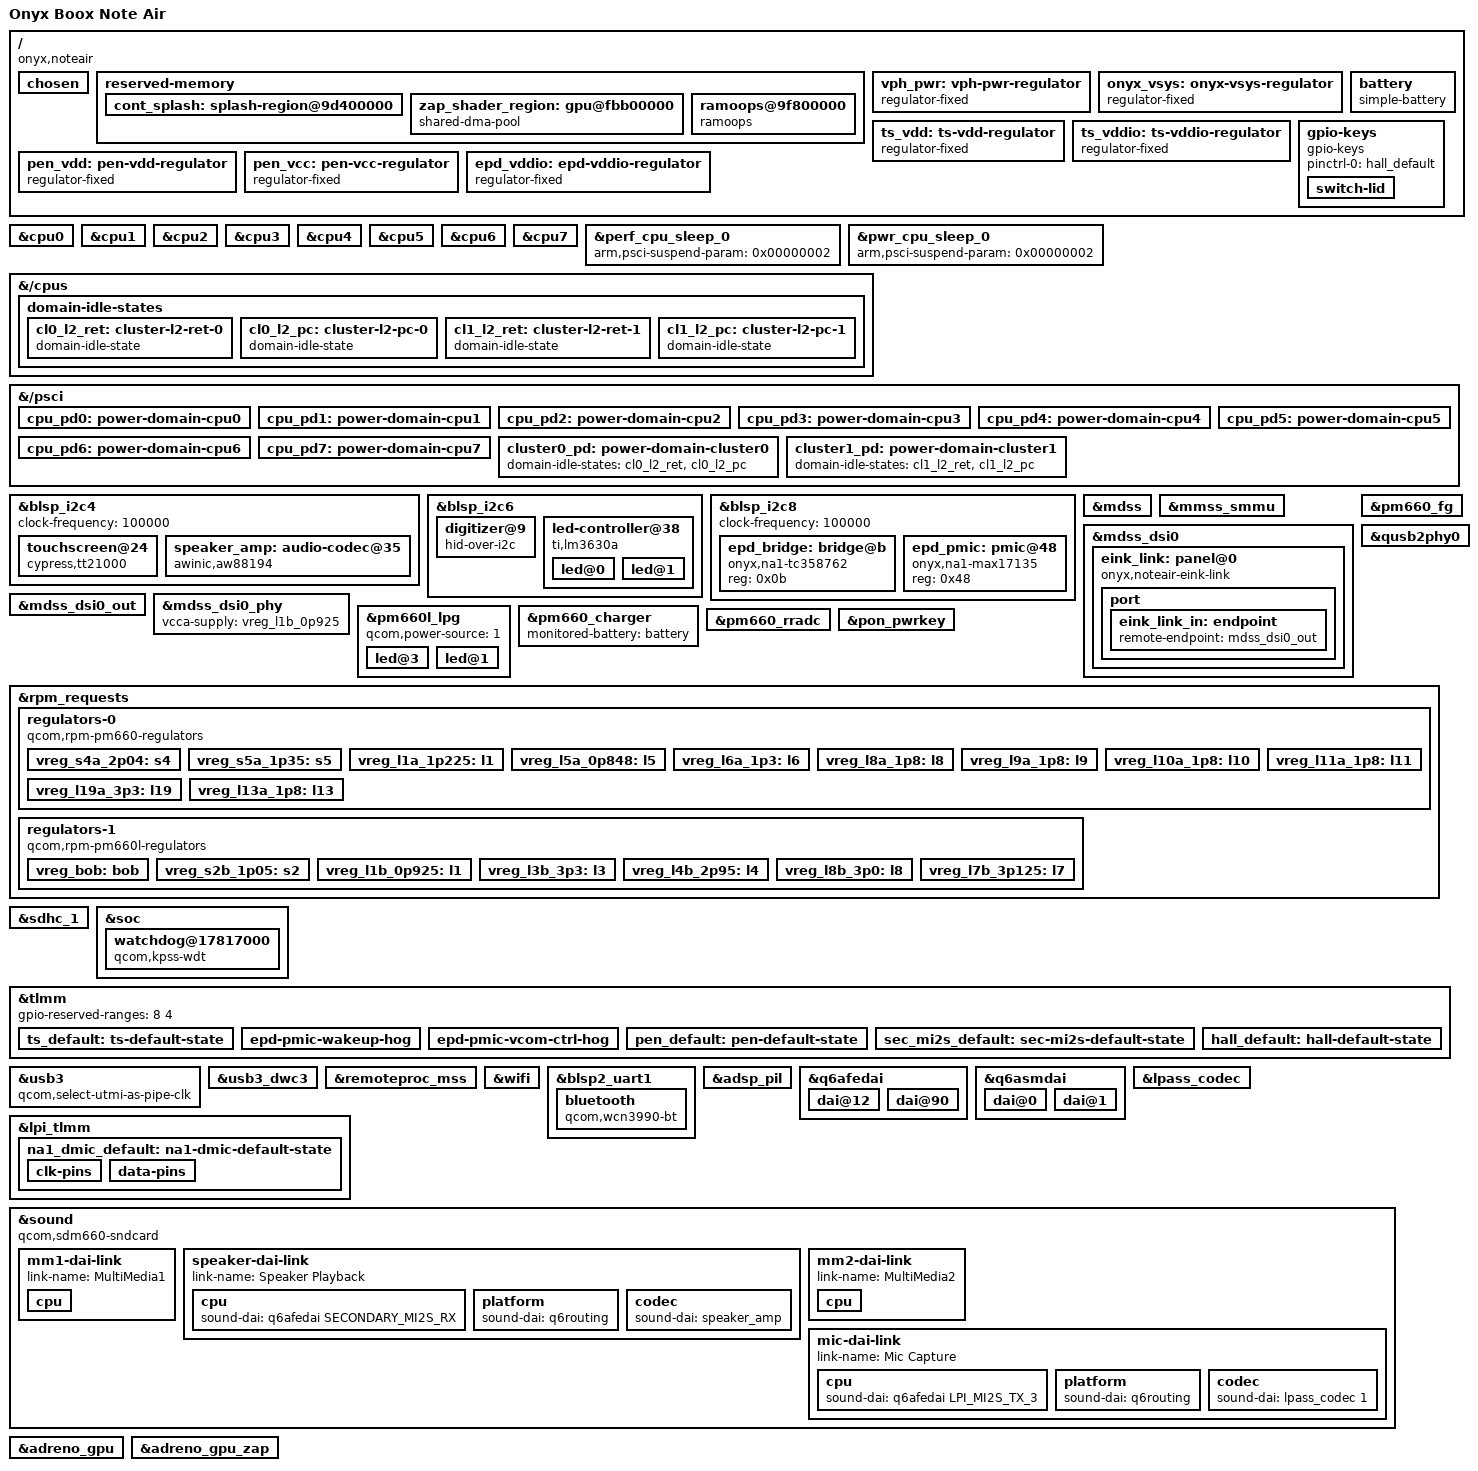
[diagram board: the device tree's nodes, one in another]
// SPDX-License-Identifier: GPL-2.0-only
/*
 * Onyx Boox Note Air (NA1) — bring-up device tree for the sdm660-mainline kernel.
 *
 * Source of every board fact: the stock Onyx DT (model
 * "SDM 636 PM660 + PM660L MTP NoteAir V02"). Template: sdm636-asus-x00td.dts.
 *
 * First bring-up: boot, pstore, USB peripheral, eMMC, watchdog, LEDs,
 * frontlight, touch, hall, charger + fuel gauge. The e-ink link, radios,
 * audio, GPU and pen came later (sections below).
 *
 * e-ink path (MDSS DPU -> DSI0 cmd mode -> TC358762 bridge -> panel, MAX17135
 * PMIC): panel-onyx-na1-link owns the link, the bridge (I2C + gpios) and the
 * PMIC rails (ENABLE reg only, gated by its hv parameter). The MAX17135 holds
 * VCOM in its NVM — never probe it with a generic driver and never write its
 * VCOM registers.
 * Also left out: Wacom pen (no mainline driver for onyx,wacom_i2c), WiFi/BT,
 * modem, audio, GPU.
 */

/dts-v1/;

#include "sdm636.dtsi"
#include "pm660.dtsi"
#include "pm660l.dtsi"
#include <dt-bindings/input/input.h>
#include <dt-bindings/input/gpio-keys.h>
#include <dt-bindings/leds/common.h>
#include <dt-bindings/sound/qcom,q6asm.h>

/*
 * Stock ramoops lives at 0x9f800000 (512 KiB). sdm630.dtsi puts a no-map
 * venus region at the same address; we don't use video decode, so the venus
 * region and device go, and ramoops takes the stock place and layout.
 */
/delete-node/ &venus_region;
/delete-node/ &venus;
/*
 * GPU zap shader: stock loads it at 0xfbb00000..0xfbb02000 (dmesg s70:
 * "subsys-pil-tz soc:qcom,kgsl-hyp: a512_zap: loading from 0xfbb00000");
 * sdm630.dtsi's region sits at 0xfed00000. As lavender does for its board.
 */
/delete-node/ &zap_shader_region;

/ {
	model = "Onyx Boox Note Air";
	compatible = "onyx,noteair", "qcom,sdm636";
	chassis-type = "tablet";

	/* ABL picks the appended DTB by these; values copied from the stock DT. */
	qcom,msm-id = <0x159 0x0>;
	qcom,board-id = <0x8 0x0>;
	qcom,pmic-id = <0x1001b 0x101011a 0x0 0x0 0x1001b 0x201011a 0x0 0x0 0x1001b 0x102001a 0x0 0x0>;

	/* No serial console: no known UART pads, and it hung suspend. */
	chosen {
	};

	reserved-memory {
		/* ABL leaves the display pipeline scanning out of this; keep it untouched. */
		cont_splash: splash-region@9d400000 {
			reg = <0x0 0x9d400000 0x0 0x23ff000>;
			no-map;
		};

		/*
		 * Same place and zone sizes as the stock kernel (ecc 0 on both), so
		 * each kernel can read what the other left: the stock pmOS initramfs
		 * saves it to /var/log/pstore/ on the next boot. Zones: dmesg 1x128K,
		 * console 128K, ftrace 64K, pmsg 64K. Survives warm reset only.
		 */
		zap_shader_region: gpu@fbb00000 {
			compatible = "shared-dma-pool";
			reg = <0x0 0xfbb00000 0x0 0x2000>;
			no-map;
		};

		ramoops@9f800000 {
			compatible = "ramoops";
			reg = <0x0 0x9f800000 0x0 0x80000>;
			record-size = <0x20000>;
			console-size = <0x20000>;
			ftrace-size = <0x10000>;
			pmsg-size = <0x10000>;
		};
	};

	vph_pwr: vph-pwr-regulator {
		compatible = "regulator-fixed";
		regulator-name = "vph_pwr";
		regulator-min-microvolt = <3700000>;
		regulator-max-microvolt = <3700000>;
		regulator-always-on;
		regulator-boot-on;
	};

	/* Stock "onyx-vsys": 1.8 V switch on TLMM 40, feeds the LM3630A. */
	onyx_vsys: onyx-vsys-regulator {
		compatible = "regulator-fixed";
		regulator-name = "onyx-vsys";
		regulator-min-microvolt = <1800000>;
		regulator-max-microvolt = <1800000>;
		gpio = <&tlmm 40 GPIO_ACTIVE_HIGH>;
		enable-active-high;
		regulator-always-on;
		regulator-boot-on;
	};

	/* Touch power switches (stock onyx-tp,vcc-ctrl-gpio / vdd-ctrl-gpio). */
	ts_vdd: ts-vdd-regulator {
		compatible = "regulator-fixed";
		regulator-name = "ts_vdd";
		regulator-min-microvolt = <3300000>;
		regulator-max-microvolt = <3300000>;
		gpio = <&tlmm 61 GPIO_ACTIVE_HIGH>;
		enable-active-high;
		vin-supply = <&vreg_l3b_3p3>;
		startup-delay-us = <5000>;
	};

	ts_vddio: ts-vddio-regulator {
		compatible = "regulator-fixed";
		regulator-name = "ts_vddio";
		regulator-min-microvolt = <1800000>;
		regulator-max-microvolt = <1800000>;
		gpio = <&tlmm 62 GPIO_ACTIVE_HIGH>;
		enable-active-high;
		vin-supply = <&vreg_l11a_1p8>;
		startup-delay-us = <5000>;
	};

	/*
	 * Pen (Wacom EMR, HID-over-I2C 2D1F:012B at blsp_i2c6 0x09; stock
	 * onyx,wacom_i2c) power switches: stock onyx-tp,vdd-ctrl-gpio 64 (1.8 V
	 * from pm660 l11) and vcc-ctrl-gpio 63 (3.0 V from pm660l l3).
	 * Bring-up: the rails are always on, so the digitizer answers
	 * before i2c-hid-of (a module) is loaded: reset (gpio75, unowned until
	 * then) is driven by hand with gpioset, the IRQ idle level read with
	 * gpioget and the HID descriptor with i2ctransfer.
	 * Drop always-on once the
	 * digitizer node below is confirmed.
	 */
	pen_vdd: pen-vdd-regulator {
		compatible = "regulator-fixed";
		regulator-name = "pen_vdd";
		regulator-min-microvolt = <1800000>;
		regulator-max-microvolt = <1800000>;
		gpio = <&tlmm 64 GPIO_ACTIVE_HIGH>;
		enable-active-high;
		vin-supply = <&vreg_l11a_1p8>;
		startup-delay-us = <5000>;
		regulator-always-on;
	};

	pen_vcc: pen-vcc-regulator {
		compatible = "regulator-fixed";
		regulator-name = "pen_vcc";
		regulator-min-microvolt = <3000000>;
		regulator-max-microvolt = <3000000>;
		gpio = <&tlmm 63 GPIO_ACTIVE_HIGH>;
		enable-active-high;
		vin-supply = <&vreg_l3b_3p3>;
		startup-delay-us = <5000>;
		regulator-always-on;
	};

	/* Stock "vddio_gpio_regulator": 3.3 V switch on TLMM 35 (e-ink bridge + PMIC IO). */
	epd_vddio: epd-vddio-regulator {
		compatible = "regulator-fixed";
		regulator-name = "epd_vddio";
		regulator-min-microvolt = <3300000>;
		regulator-max-microvolt = <3300000>;
		gpio = <&tlmm 35 GPIO_ACTIVE_HIGH>;
		enable-active-high;
		vin-supply = <&onyx_vsys>;
	};

	/*
	 * Stock battery profile "4616397_idea_h6620_byd_3000mah": 3000 mAh, float 4.40 V,
	 * FG cutoff 3.30 V; stock charger fcc-max 1.5 A. The charger driver programs the
	 * float voltage and charge current from these — keep them at the stock values.
	 */
	battery: battery {
		compatible = "simple-battery";
		charge-full-design-microamp-hours = <3000000>;
		voltage-min-design-microvolt = <3300000>;
		voltage-max-design-microvolt = <4400000>;
		constant-charge-current-max-microamp = <1500000>;
	};

	gpio-keys {
		compatible = "gpio-keys";
		pinctrl-names = "default";
		pinctrl-0 = <&hall_default>;

		/* Stock onyx-hall: TLMM 105, pulled up, low = cover closed. ABL reads it too. */
		switch-lid {
			label = "Hall Effect Sensor";
			gpios = <&tlmm 105 GPIO_ACTIVE_LOW>;
			linux,input-type = <EV_SW>;
			linux,code = <SW_LID>;
			linux,can-disable;
			wakeup-source;
		};

		/* The stock DT also has volume-up on PM660L gpio 7, but the NA1 has no such button. */
	};
};

/* Stock i2c@c178000: Cypress/Parade touch. */
/*
 * No cpufreq on mainline yet: the clusters stay where the boot chain left them, which is
 * silver (0x801, &cpu4-7) at 1382.4 MHz and gold (0x800, &cpu0-3) at only 600 MHz (measured,
 * cycles/s). sdm660.dtsi's 1024/640 then sends heavy work to the SLOWER cores. Measured with
 * both pinned: zlib 3.6 s silver vs 5.9 s gold, Python 2.2 vs 2.5 s -> gold ~0.6-0.9x silver.
 * sdm636-cpufreq.dtsi (included below) undoes these now that cpufreq works;
 * they stay for a build without it.
 */
&cpu0 {
	capacity-dmips-mhz = <768>;
	/delete-property/ cpu-idle-states;
	power-domains = <&cpu_pd0>;
	power-domain-names = "psci";
};
&cpu1 {
	capacity-dmips-mhz = <768>;
	/delete-property/ cpu-idle-states;
	power-domains = <&cpu_pd1>;
	power-domain-names = "psci";
};
&cpu2 {
	capacity-dmips-mhz = <768>;
	/delete-property/ cpu-idle-states;
	power-domains = <&cpu_pd2>;
	power-domain-names = "psci";
};
&cpu3 {
	capacity-dmips-mhz = <768>;
	/delete-property/ cpu-idle-states;
	power-domains = <&cpu_pd3>;
	power-domain-names = "psci";
};
&cpu4 {
	capacity-dmips-mhz = <1024>;
	/delete-property/ cpu-idle-states;
	power-domains = <&cpu_pd4>;
	power-domain-names = "psci";
};
&cpu5 {
	capacity-dmips-mhz = <1024>;
	/delete-property/ cpu-idle-states;
	power-domains = <&cpu_pd5>;
	power-domain-names = "psci";
};
&cpu6 {
	capacity-dmips-mhz = <1024>;
	/delete-property/ cpu-idle-states;
	power-domains = <&cpu_pd6>;
	power-domain-names = "psci";
};
&cpu7 {
	capacity-dmips-mhz = <1024>;
	/delete-property/ cpu-idle-states;
	power-domains = <&cpu_pd7>;
	power-domain-names = "psci";
};

/*
 * CPU / cluster idle. The NA1's TZ runs PSCI in OS-initiated mode and
 * refuses platform-coordinated ("psci: [Firmware Bug]: failed to set PC mode:
 * -3" = DENIED), so sdm630.dtsi's flat cluster states (0x400000f2..f4) were
 * all rejected (millions of times; the clusters never powered down), and its
 * core retention 0x40000002 as well (retention is no power-down: bit 30 = 0).
 * State IDs as the stock 4.4 lpm-levels composes them: cpu mode [3:0] (2 ret,
 * 3 pc), L2 mode [7:4] (3 ret, 4 pc), affinity level [25:24], bit 30 = cpu
 * power-down. A cluster state is the whole composite, requested by the last
 * CPU of the cluster going down (OSI, genpd). The system/CCI level (needs an
 * RPM handshake) is left out.
 */
&perf_cpu_sleep_0 { arm,psci-suspend-param = <0x00000002>; };
&pwr_cpu_sleep_0 { arm,psci-suspend-param = <0x00000002>; };

&{/cpus} {
	domain-idle-states {
		cl0_l2_ret: cluster-l2-ret-0 {
			compatible = "domain-idle-state";
			arm,psci-suspend-param = <0x41000033>;
			entry-latency-us = <338>;
			exit-latency-us = <423>;
			min-residency-us = <2000>;
		};
		cl0_l2_pc: cluster-l2-pc-0 {
			compatible = "domain-idle-state";
			arm,psci-suspend-param = <0x41000043>;
			entry-latency-us = <515>;
			exit-latency-us = <1821>;
			min-residency-us = <5000>;
		};
		cl1_l2_ret: cluster-l2-ret-1 {
			compatible = "domain-idle-state";
			arm,psci-suspend-param = <0x41000033>;
			entry-latency-us = <332>;
			exit-latency-us = <368>;
			min-residency-us = <2000>;
		};
		cl1_l2_pc: cluster-l2-pc-1 {
			compatible = "domain-idle-state";
			arm,psci-suspend-param = <0x41000043>;
			entry-latency-us = <545>;
			exit-latency-us = <1609>;
			min-residency-us = <5000>;
		};
	};
};

&{/psci} {
	cpu_pd0: power-domain-cpu0 {
		#power-domain-cells = <0>;
		power-domains = <&cluster1_pd>;
		domain-idle-states = <&perf_cpu_sleep_0 &perf_cpu_sleep_1>;
	};
	cpu_pd1: power-domain-cpu1 {
		#power-domain-cells = <0>;
		power-domains = <&cluster1_pd>;
		domain-idle-states = <&perf_cpu_sleep_0 &perf_cpu_sleep_1>;
	};
	cpu_pd2: power-domain-cpu2 {
		#power-domain-cells = <0>;
		power-domains = <&cluster1_pd>;
		domain-idle-states = <&perf_cpu_sleep_0 &perf_cpu_sleep_1>;
	};
	cpu_pd3: power-domain-cpu3 {
		#power-domain-cells = <0>;
		power-domains = <&cluster1_pd>;
		domain-idle-states = <&perf_cpu_sleep_0 &perf_cpu_sleep_1>;
	};
	cpu_pd4: power-domain-cpu4 {
		#power-domain-cells = <0>;
		power-domains = <&cluster0_pd>;
		domain-idle-states = <&pwr_cpu_sleep_0 &pwr_cpu_sleep_1>;
	};
	cpu_pd5: power-domain-cpu5 {
		#power-domain-cells = <0>;
		power-domains = <&cluster0_pd>;
		domain-idle-states = <&pwr_cpu_sleep_0 &pwr_cpu_sleep_1>;
	};
	cpu_pd6: power-domain-cpu6 {
		#power-domain-cells = <0>;
		power-domains = <&cluster0_pd>;
		domain-idle-states = <&pwr_cpu_sleep_0 &pwr_cpu_sleep_1>;
	};
	cpu_pd7: power-domain-cpu7 {
		#power-domain-cells = <0>;
		power-domains = <&cluster0_pd>;
		domain-idle-states = <&pwr_cpu_sleep_0 &pwr_cpu_sleep_1>;
	};
	/* cpu4-7 (the "pwr" states in sdm630.dtsi) */
	cluster0_pd: power-domain-cluster0 {
		#power-domain-cells = <0>;
		domain-idle-states = <&cl0_l2_ret &cl0_l2_pc>;
	};
	/* cpu0-3 */
	cluster1_pd: power-domain-cluster1 {
		#power-domain-cells = <0>;
		domain-idle-states = <&cl1_l2_ret &cl1_l2_pc>;
	};
};

&blsp_i2c4 {
	clock-frequency = <100000>;
	status = "okay";

	touchscreen@24 {
		compatible = "cypress,tt21000";
		reg = <0x24>;
		/* level, not edge: INT stays low while reports are
		 * queued, so a missed falling edge left touch dead for good
		 * (irq count frozen, na1-touchd gone) */
		interrupts-extended = <&tlmm 67 IRQ_TYPE_LEVEL_LOW>;
		reset-gpios = <&tlmm 66 GPIO_ACTIVE_LOW>;
		vdd-supply = <&ts_vdd>;
		vddio-supply = <&ts_vddio>;
		pinctrl-names = "default";
		pinctrl-0 = <&ts_default>;
		/* report like the stock cyttsp5_mt (na1-touchd and the X
		 * calibration matrix assume its axes): mainline's y runs the
		 * other way (portrait taps came out mirrored left/right) */
		touchscreen-inverted-y;
	};

	/*
	 * Speaker amp: Awinic AW88194 (chip id 0x1806), fed from SEC_MI2S SD1.
	 * Stock: aw881xx_smartpa@35, reset-gpio TLMM 94, no irq, no supply;
	 * its tuning files come from the vendor partition (na1-ml-radio links
	 * them to /lib/firmware/awinic).
	 */
	speaker_amp: audio-codec@35 {
		compatible = "awinic,aw88194";
		reg = <0x35>;
		reset-gpios = <&tlmm 94 GPIO_ACTIVE_LOW>;
		firmware-name = "awinic/aw881xx_na1_spk";
		#sound-dai-cells = <0>;
	};
};

/* Stock i2c@c1b6000: LM3630A frontlight, Wacom pen @09 (left out), NFC (disabled on stock). */
&blsp_i2c6 {
	status = "okay";

	/*
	 * Pen: stock wacom@09 (onyx,wacom_i2c) = HID-over-I2C Wacom EMR 2D1F:012B.
	 * UNCONFIRMED until probed by hand: IRQ polarity (level-low per the
	 * HID-over-I2C spec and the stock pull-up; stock requests flag 1 =
	 * rising edge) and reset polarity (assumed RESET_N).
	 */
	digitizer@9 {
		compatible = "hid-over-i2c";
		reg = <0x09>;
		hid-descr-addr = <0x0001>;
		interrupts-extended = <&tlmm 74 IRQ_TYPE_LEVEL_LOW>;
		reset-gpios = <&tlmm 75 GPIO_ACTIVE_LOW>;
		vdd-supply = <&pen_vdd>;
		vddl-supply = <&pen_vcc>;
		post-power-on-delay-ms = <20>;
		post-reset-deassert-delay-ms = <100>;
		pinctrl-names = "default";
		pinctrl-0 = <&pen_default>;
	};

	led-controller@38 {
		compatible = "ti,lm3630a";
		reg = <0x38>;
		enable-gpios = <&tlmm 76 GPIO_ACTIVE_HIGH>;
		#address-cells = <1>;
		#size-cells = <0>;

		/*
		 * Two strings (warm/cold). A low default on bank A doubles as a
		 * "kernel got this far" signal: the e-ink shows nothing new.
		 */
		led@0 {
			reg = <0>;
			led-sources = <0>;
			label = "frontlight-a";
			default-brightness = <24>;
			max-brightness = <255>;
		};

		led@1 {
			reg = <1>;
			led-sources = <1>;
			label = "frontlight-b";
			default-brightness = <0>;
			max-brightness = <255>;
		};
	};
};

/*
 * Stock i2c@c1b8000 (100 kHz): TC358762 @0b and MAX17135 @48 (e-ink). Both
 * nodes are plain I2C clients with Onyx-specific compatibles that no driver
 * binds: panel-onyx-na1-link reaches them by phandle and sequences them. The
 * MAX17135 VCOM lives in its NVM: never write it (regs 0x08/0x0C), and never
 * bind a generic max17135/regulator driver here.
 */
&blsp_i2c8 {
	status = "okay";
	clock-frequency = <100000>;

	epd_bridge: bridge@b {
		compatible = "onyx,na1-tc358762";
		reg = <0x0b>;
	};

	epd_pmic: pmic@48 {
		compatible = "onyx,na1-max17135";
		reg = <0x48>;
	};
};

/*
 * EPDC bring-up step 2: the DSI link alone. Stock DSI0: vdda 1.2 V (pm660
 * l1), PHY 0.9 V (pm660l l1), 2 lanes, command mode. Stock's LCD-template
 * extras (lab/ibb bias, reset gpio 53, TE gpio 59) are not used by the e-ink
 * path and are left out. No TE: DPU's watchdog timer paces command mode.
 */
&mdss {
	status = "okay";
};

&mmss_smmu {
	status = "okay";
};

&mdss_dsi0 {
	#address-cells = <1>;
	#size-cells = <0>;

	vdd-supply = <&vreg_l1b_0p925>;
	/*
	 * Stock vdda-1p2-supply = pm660_l6 (1.2-1.32 V, 12.56 mA), the LDO it
	 * shares with the WCN RF and the BT PA; l1a was the reference board's.
	 * With l1a here the DSI analog side ran only while WiFi or BT held l6,
	 * and the PLL died when the last of them let go mid-link (the power-key
	 * display stall, 2026-10-02).
	 */
	vdda-supply = <&vreg_l6a_1p3>;
	/*
	 * Stock command-mode byte order (downstream "rgb_swap_grb"; stock
	 * onyx_epdc_sdm660_mdp_reg_update writes CMD_CFG0 = 0x40008). With an
	 * XBGR8888 framebuffer (SSPP unpack 0x03010002 = stock) the wire carries
	 * the stock frame words byte-for-byte. Patch 0003.
	 */
	qcom,cmd-rgb-swap-grb;
	status = "okay";

	/*
	 * Stock tc358762@0b: osc_enable 55, mode0 43 (= MD0), reset 42 (active
	 * low), vddc 1.2 V switch 45, vdd1v8 pm660_l11, vddio TLMM 35 switch.
	 * Stock max17135@48: vdd (V3P3) pm660l_l8 3.0 V, pwrgood 52.
	 */
	eink_link: panel@0 {
		compatible = "onyx,noteair-eink-link";
		reg = <0>;
		/* the host's link clocks: HV only while they run at the mode's rate */
		clocks = <&mmcc MDSS_PCLK0_CLK>, <&mmcc MDSS_BYTE0_CLK>,
			 <&rpmcc RPM_SMD_RF_CLK1_PIN>;
		clock-names = "pclk", "byte", "rfclk";
		/* VDDMX held while the link is up (driver param mx_level, default
		 * off): the power-key display stall, 2026-10-02 */
		power-domains = <&rpmpd RPMPD_VDDMX_AO>;
		power-domain-names = "mx";
		/* the DSI LDOs' parents: load votes while the link is up
		 * (driver params hold_rfclk / rail_load_ua, default off) */
		s5a-supply = <&vreg_s5a_1p35>;
		s2b-supply = <&vreg_s2b_1p05>;
		/* the WCN rails, held while the link is up (param hold_wcn, default off) */
		wcn-l5-supply = <&vreg_l5a_0p848>;
		wcn-l9-supply = <&vreg_l9a_1p8>;
		wcn-l6-supply = <&vreg_l6a_1p3>;
		wcn-l19-supply = <&vreg_l19a_3p3>;

		onyx,bridge = <&epd_bridge>;
		onyx,pmic = <&epd_pmic>;
		osc-gpios = <&tlmm 55 GPIO_ACTIVE_HIGH>;
		mode0-gpios = <&tlmm 43 GPIO_ACTIVE_HIGH>;
		reset-gpios = <&tlmm 42 GPIO_ACTIVE_LOW>;
		vddc-gpios = <&tlmm 45 GPIO_ACTIVE_HIGH>;
		pmic-pwrgood-gpios = <&tlmm 52 GPIO_ACTIVE_HIGH>;
		vdd1v8-supply = <&vreg_l11a_1p8>;
		vddio-supply = <&epd_vddio>;
		v3p3-supply = <&vreg_l8b_3p0>;

		port {
			eink_link_in: endpoint {
				remote-endpoint = <&mdss_dsi0_out>;
			};
		};
	};
};

&mdss_dsi0_out {
	data-lanes = <0 1>;
	qcom,te-source = "timer0";
	remote-endpoint = <&eink_link_in>;
};

&mdss_dsi0_phy {
	vcca-supply = <&vreg_l1b_0p925>;
	status = "okay";
};

&pm660l_lpg {
	#address-cells = <1>;
	#size-cells = <0>;
	qcom,power-source = <1>;
	status = "okay";

	/* Tri-LED behind the power-button pinhole; channel 3 = red (as lavender). */
	led@3 {
		reg = <3>;
		color = <LED_COLOR_ID_RED>;
		function = LED_FUNCTION_HEARTBEAT;
		/*
		 * No default trigger: the heartbeat was for the
		 * overnight-stall hunt and cost ~10 wakeups/s + the LED current.
		 * Debug: echo heartbeat > /sys/class/leds/red:heartbeat/trigger
		 */
	};

	/* Assumed blue (stock qcom,id 5); lights solid on panic. */
	led@1 {
		reg = <1>;
		color = <LED_COLOR_ID_BLUE>;
		function = LED_FUNCTION_INDICATOR;
		linux,default-trigger = "panic";
	};
};

&pm660_charger {
	monitored-battery = <&battery>;
	status = "okay";
};

&pm660_fg {
	monitored-battery = <&battery>;
	power-supplies = <&pm660_charger>;
	status = "okay";
};

&pm660_rradc {
	status = "okay";
};

&pon_pwrkey {
	status = "okay";
};

&qusb2phy0 {
	vdd-supply = <&vreg_l1b_0p925>;
	vdda-pll-supply = <&vreg_l10a_1p8>;
	vdda-phy-dpdm-supply = <&vreg_l7b_3p125>;
	status = "okay";
};

&rpm_requests {
	regulators-0 {
		compatible = "qcom,rpm-pm660-regulators";

		vdd_s1-supply = <&vph_pwr>;
		vdd_s2-supply = <&vph_pwr>;
		vdd_s3-supply = <&vph_pwr>;
		vdd_s4-supply = <&vph_pwr>;
		vdd_s5-supply = <&vph_pwr>;
		vdd_s6-supply = <&vph_pwr>;

		vdd_l1_l6_l7-supply = <&vreg_s5a_1p35>;
		vdd_l2_l3-supply = <&vreg_s2b_1p05>;
		vdd_l5-supply = <&vreg_s2b_1p05>;
		vdd_l8_l9_l10_l11_l12_l13_l14-supply = <&vreg_s4a_2p04>;
		vdd_l15_l16_l17_l18_l19-supply = <&vreg_bob>;

		/* S1A-S3A are CPR/OSM-managed; not touched. */

		vreg_s4a_2p04: s4 {
			regulator-min-microvolt = <1805000>;
			regulator-max-microvolt = <2040000>;
			regulator-enable-ramp-delay = <200>;
			regulator-always-on;
		};

		/*
		 * Our vote 1.328 V, not 1.224 (2026-10-02, the power-key display
		 * stall): s5a feeds l1a (DSI vdda, 1.256 V out) and l6a (WCN RF).
		 * With WiFi on, l6a's need held s5a at 1.328 V; WCN off dropped it
		 * to 1.296 V (SPMI readback), and a WCN shutdown within ~5 ms of
		 * the DSI PLL lock killed the PLL every time (wififlap fine sweep,
		 * 3/3 real presses). Votes only while a child is on.
		 */
		vreg_s5a_1p35: s5 {
			regulator-min-microvolt = <1328000>;
			regulator-max-microvolt = <1350000>;
			regulator-enable-ramp-delay = <200>;
			regulator-allow-set-load;
		};

		/* stock pm660_l1: only the UFS ref clock (not on this eMMC board);
		 * unused here since the DSI vdda moved to l6 (2026-10-02) */
		vreg_l1a_1p225: l1 {
			regulator-min-microvolt = <1200000>;
			regulator-max-microvolt = <1250000>;
			regulator-enable-ramp-delay = <250>;
			regulator-allow-set-load;
		};

		/* WCN3990 cx/mx (stock pm660_l5 0.848 V) */
		vreg_l5a_0p848: l5 {
			regulator-min-microvolt = <525000>;
			regulator-max-microvolt = <950000>;
			regulator-enable-ramp-delay = <250>;
		};

		/* DSI0 vdda (stock "vdda-1p2" 1.2-1.32 V) + WCN3990 rfa + BT pa
		 * (stock pm660_l6 1.2-1.37 V) */
		vreg_l6a_1p3: l6 {
			regulator-min-microvolt = <1200000>;
			regulator-max-microvolt = <1370000>;
			regulator-enable-ramp-delay = <250>;
			regulator-allow-set-load;
		};

		/* eMMC vqmmc (stock pm660_l8 1.75–1.9 V) */
		vreg_l8a_1p8: l8 {
			regulator-min-microvolt = <1750000>;
			regulator-max-microvolt = <1800000>;
			regulator-enable-ramp-delay = <250>;
			regulator-system-load = <325000>;
			regulator-allow-set-load;
		};

		/* WCN3990 xo / BT core (stock pm660_l9 1.75–1.9 V) */
		vreg_l9a_1p8: l9 {
			regulator-min-microvolt = <1750000>;
			regulator-max-microvolt = <1900000>;
			regulator-enable-ramp-delay = <250>;
			regulator-allow-set-load;
		};

		vreg_l10a_1p8: l10 {
			regulator-min-microvolt = <1780000>;
			regulator-max-microvolt = <1950000>;
			regulator-enable-ramp-delay = <250>;
			regulator-allow-set-load;
		};

		/* touch vddio source (stock pm660_l11 1.78–1.95 V) */
		vreg_l11a_1p8: l11 {
			regulator-min-microvolt = <1780000>;
			regulator-max-microvolt = <1950000>;
			regulator-enable-ramp-delay = <250>;
		};

		/* WCN3990 ch0 / BT ldo (stock pm660_l19 3.312–3.4 V) */
		vreg_l19a_3p3: l19 {
			regulator-min-microvolt = <3312000>;
			regulator-max-microvolt = <3400000>;
			regulator-enable-ramp-delay = <250>;
			regulator-allow-set-load;
		};

		/* LPDDR4 supply: never turn off. */
		vreg_l13a_1p8: l13 {
			regulator-min-microvolt = <1780000>;
			regulator-max-microvolt = <1950000>;
			regulator-enable-ramp-delay = <250>;
			regulator-boot-on;
			regulator-always-on;
		};
	};

	regulators-1 {
		compatible = "qcom,rpm-pm660l-regulators";

		vdd_s1-supply = <&vph_pwr>;
		vdd_s2-supply = <&vph_pwr>;
		vdd_s3_s4-supply = <&vph_pwr>;
		vdd_s5-supply = <&vph_pwr>;
		vdd_s6-supply = <&vph_pwr>;

		vdd_l1_l9_l10-supply = <&vreg_s2b_1p05>;
		vdd_l2-supply = <&vreg_bob>;
		vdd_l3_l5_l7_l8-supply = <&vreg_bob>;
		vdd_l4_l6-supply = <&vreg_bob>;
		vdd_bob-supply = <&vph_pwr>;

		/* Also the stock hall sensor supply (hall_vdd-supply = pm660l_bob). */
		vreg_bob: bob {
			regulator-min-microvolt = <3300000>;
			regulator-max-microvolt = <3600000>;
			regulator-enable-ramp-delay = <500>;
			regulator-always-on;
		};

		vreg_s2b_1p05: s2 {
			regulator-min-microvolt = <1050000>;
			regulator-max-microvolt = <1050000>;
			regulator-enable-ramp-delay = <200>;
			regulator-allow-set-load;
		};

		/*
		 * DSI0 PHY vdd: stock "vdda-0p9" 0.88 - 0.925 V (qcom,phy-supply-
		 * entries). The mainline 14 nm PHY only votes load, so the floor is
		 * what it gets: at 0.8 V the DSI PLL once failed to lock, the
		 * link came back at ~1/4 rate and over-drove the e-ink panel.
		 */
		vreg_l1b_0p925: l1 {
			regulator-min-microvolt = <880000>;
			regulator-max-microvolt = <925000>;
			regulator-enable-ramp-delay = <250>;
			regulator-allow-set-load;
		};

		/* touch vdd + pen vcc source (stock pm660l_l3 1.7–3.6 V; the stock pen driver sets
		 * it to 3.0 V, "vcc-voltage:3000000"). The fixed pen/touch switches don't set their
		 * parent's voltage, so with min 1.7 V it sat at 1.704 V and the digitizer never ACKed. */
		vreg_l3b_3p3: l3 {
			regulator-min-microvolt = <3000000>;
			regulator-max-microvolt = <3300000>;
			regulator-enable-ramp-delay = <250>;
			regulator-allow-set-load;
		};

		/* eMMC vmmc (stock pm660l_l4 2.95–3.3 V) */
		vreg_l4b_2p95: l4 {
			regulator-min-microvolt = <2944000>;
			regulator-max-microvolt = <2952000>;
			regulator-enable-ramp-delay = <250>;
			regulator-min-microamp = <200>;
			regulator-max-microamp = <600000>;
			regulator-system-load = <570000>;
			regulator-allow-set-load;
		};

		/* e-ink V3P3: MAX17135 vdd + bridge panelvdd (stock pm660l_l8, vdd_uV 3.0 V) */
		vreg_l8b_3p0: l8 {
			regulator-min-microvolt = <3000000>;
			regulator-max-microvolt = <3000000>;
			regulator-enable-ramp-delay = <250>;
		};

		vreg_l7b_3p125: l7 {
			regulator-min-microvolt = <2700000>;
			regulator-max-microvolt = <3125000>;
			regulator-enable-ramp-delay = <250>;
		};
	};
};

&sdhc_1 {
	bus-width = <8>;
	non-removable;
	/*
	 * HS400 + enhanced strobe + command queueing (2026-10-04): the card is
	 * eMMC 5.1 (ext_csd rev 8, CARD_TYPE 0x57 = HS400/HS200 1.8 V,
	 * STROBE_SUPPORT 1, CMDQ depth 16); stock runs HS400 at 384 MHz
	 * (qcom,bus-speed-mode HS400_1p8v). HS200 stays as the fallback.
	 */
	supports-cqe;
	mmc-ddr-1_8v;
	mmc-hs200-1_8v;
	mmc-hs400-1_8v;
	mmc-hs400-enhanced-strobe;
	vmmc-supply = <&vreg_l4b_2p95>;
	vqmmc-supply = <&vreg_l8a_1p8>;
	status = "okay";
};

&soc {
	/* Stock qcom,wdt@17817000 (bark = GIC SPI 3). Petted by the initramfs. */
	watchdog@17817000 {
		compatible = "qcom,kpss-wdt";
		reg = <0x17817000 0x1000>;
		clocks = <&sleep_clk>;
		interrupts = <GIC_SPI 3 IRQ_TYPE_EDGE_RISING>;
		timeout-sec = <20>;
	};
};

&tlmm {
	/*
	 * TZ-owned pins; touching them is an XPU violation -> 900E crash dump
	 * (seen on NA1 when reading the global gpio debugfs). 8-11 is what
	 * every sdm660 board uses; the NA1 range is NOT confirmed. If the first
	 * boot dies in pinctrl probe, widen this first.
	 */
	gpio-reserved-ranges = <8 4>;

	ts_default: ts-default-state {
		pins = "gpio67";
		function = "gpio";
		drive-strength = <2>;
		bias-disable;
	};

	/*
	 * MAX17135 WAKEUP (stock gpio_pmic_wakeup 93) and VCOM_CTRL (106) held
	 * low, as the stock driver requests them and leaves them (pass_num 2,
	 * control_mode 0). NOT a protection by itself: stock switches the HV
	 * rails with ENABLE reg 0x09 over I2C, and panel-onyx-na1-link does the
	 * same (only with its hv parameter set).
	 */
	epd-pmic-wakeup-hog {
		gpio-hog;
		gpios = <93 GPIO_ACTIVE_HIGH>;
		output-low;
		line-name = "epd-pmic-wakeup";
	};

	epd-pmic-vcom-ctrl-hog {
		gpio-hog;
		gpios = <106 GPIO_ACTIVE_HIGH>;
		output-low;
		line-name = "epd-pmic-vcom-ctrl";
	};

	pen_default: pen-default-state {
		pins = "gpio74", "gpio75";	/* irq, reset; 63/64 belong to the rails */
		function = "gpio";
		drive-strength = <4>;
		bias-pull-up;			/* as stock */
	};

	/* SCK, WS, SD1 (stock msm-dai-q6-mi2s-sec: rx-lines 0x2 = SD1, 8 mA, no bias) */
	sec_mi2s_default: sec-mi2s-default-state {
		pins = "gpio24", "gpio25", "gpio27";
		function = "sec_mi2s";
		drive-strength = <8>;
		bias-disable;
	};

	hall_default: hall-default-state {
		pins = "gpio105";
		function = "gpio";
		drive-strength = <2>;
		bias-pull-up;
	};
};

&usb3 {
	qcom,select-utmi-as-pipe-clk;
	status = "okay";
};

/* USB 2.0 only. Peripheral-only until PM660 Type-C detection is wired up. */
&usb3_dwc3 {
	dr_mode = "peripheral";
	maximum-speed = "high-speed";
	phys = <&qusb2phy0>;
	phy-names = "usb2-phy";
	status = "okay";
};

/*
 * WiFi = WCN3990 (ath10k_snoc); its firmware runs on the modem DSP, booted by
 * q6v5-mss (MBA) like stock. Firmware from the NA1's own modem partition;
 * the drivers are modules, so
 * nothing starts until they are loaded.
 */
&remoteproc_mss {
	firmware-name = "qcom/sdm636/onyx/noteair/mba.mbn",
			"qcom/sdm636/onyx/noteair/modem.mdt";
	status = "okay";
};

&wifi {
	vdd-0.8-cx-mx-supply = <&vreg_l5a_0p848>;
	vdd-1.8-xo-supply = <&vreg_l9a_1p8>;
	vdd-1.3-rfa-supply = <&vreg_l6a_1p3>;
	vdd-3.3-ch0-supply = <&vreg_l19a_3p3>;
	/* per-board BDF dir: ath10k/WCN3990/hw1.0/onyx_noteair/ (linux-firmware's
	 * generic board-id 0xff entry is sdm845 calibration) */
	firmware-name = "onyx_noteair";
	status = "okay";
};

/* Bluetooth = the WCN3990 BT core on BLSP2 UART1 (stock c1af000, TLMM 16-19) */
&blsp2_uart1 {
	status = "okay";

	bluetooth {
		compatible = "qcom,wcn3990-bt";
		vddio-supply = <&vreg_l13a_1p8>;
		vddxo-supply = <&vreg_l9a_1p8>;
		vddrf-supply = <&vreg_l6a_1p3>;
		vddch0-supply = <&vreg_l19a_3p3>;
		max-speed = <3200000>;
	};
};

/*
 * Audio: the ADSP (q6 APR services) and the speaker path
 * MultiMedia1 -> SECONDARY_MI2S_RX -> AW88194. The mic is below.
 */
&adsp_pil {
	firmware-name = "qcom/sdm636/onyx/noteair/adsp.mdt";
};

&q6afedai {
	dai@12 {
		reg = <SECONDARY_MI2S_RX>;
		qcom,sd-lines = <1>;
	};

	/* internal codec TX1/TX2 (DEC1/DEC2) on SD0 */
	dai@90 {
		reg = <LPI_MI2S_TX_3>;
		qcom,sd-lines = <0>;
	};
};

/* one playback-only and one capture-only PCM: PipeWire sees a speaker and a mic */
&q6asmdai {
	dai@0 {
		reg = <MSM_FRONTEND_DAI_MULTIMEDIA1>;
		direction = <Q6ASM_DAI_RX>;
	};

	dai@1 {
		reg = <MSM_FRONTEND_DAI_MULTIMEDIA2>;
		direction = <Q6ASM_DAI_TX>;
	};
};

/*
 * Mic: DMIC4 = the second DMIC pair (stock dmic34: LPI gpio28 clk,
 * gpio29 data) -> internal digital codec DEC1/DEC2 -> INT3_MI2S_TX, as stock's
 * speaker-mic path. The PM660L analog codec is not used (no jack, no AMIC).
 * DMIC3/4 needs patches/0005 (the mainline codec driver stops at DMIC2).
 */
&lpass_codec {
	status = "okay";
};

&lpi_tlmm {
	na1_dmic_default: na1-dmic-default-state {
		clk-pins {
			pins = "gpio28";
			function = "dmic2_clk";
			drive-strength = <8>;
		};

		data-pins {
			pins = "gpio29";
			function = "dmic2_data";
			drive-strength = <8>;
			input-enable;
		};
	};
};

&sound {
	compatible = "qcom,sdm660-sndcard";
	model = "Onyx Note Air";
	pinctrl-names = "default";
	pinctrl-0 = <&sec_mi2s_default>, <&na1_dmic_default>;

	/* sink, source pairs. The mic: the codec's "Digital Mic1" source widget
	 * feeds DMIC4 — without a source endpoint DAPM never powers the capture
	 * path (recording ran but every sample was 0, all widgets Off) */
	audio-routing = "Digital TX_I2S_CLK", "Digital MCLK",
			"Digital DMIC4", "Digital Digital Mic1";

	mm1-dai-link {
		link-name = "MultiMedia1";

		cpu {
			sound-dai = <&q6asmdai MSM_FRONTEND_DAI_MULTIMEDIA1>;
		};
	};

	speaker-dai-link {
		link-name = "Speaker Playback";

		cpu {
			sound-dai = <&q6afedai SECONDARY_MI2S_RX>;
		};

		platform {
			sound-dai = <&q6routing>;
		};

		codec {
			sound-dai = <&speaker_amp>;
		};
	};

	mm2-dai-link {
		link-name = "MultiMedia2";

		cpu {
			sound-dai = <&q6asmdai MSM_FRONTEND_DAI_MULTIMEDIA2>;
		};
	};

	mic-dai-link {
		link-name = "Mic Capture";

		cpu {
			sound-dai = <&q6afedai LPI_MI2S_TX_3>;
		};

		platform {
			sound-dai = <&q6routing>;
		};

		codec {
			sound-dai = <&lpass_codec 1>;
		};
	};
};

/*
 * GPU: Adreno 509. Microcode a530_pm4/pfp and the signed a512_zap
 * (509 uses the 512 zap) come from the NA1's vendor partition, linked by
 * na1-ml-boot before the desktop opens the DRM device (the GPU loads on the
 * first open).
 */
&adreno_gpu {
	status = "okay";
};

&adreno_gpu_zap {
	firmware-name = "qcom/sdm636/onyx/noteair/a512_zap.mdt";
	memory-region = <&zap_shader_region>;
};

#include "sdm636-cpufreq.dtsi"
#include "sdm636-cpubw.dtsi"
#include "sdm636-cpubw-max.dtsi"

#include "sdm636-onyx-noteair-sleep.dtsi"
